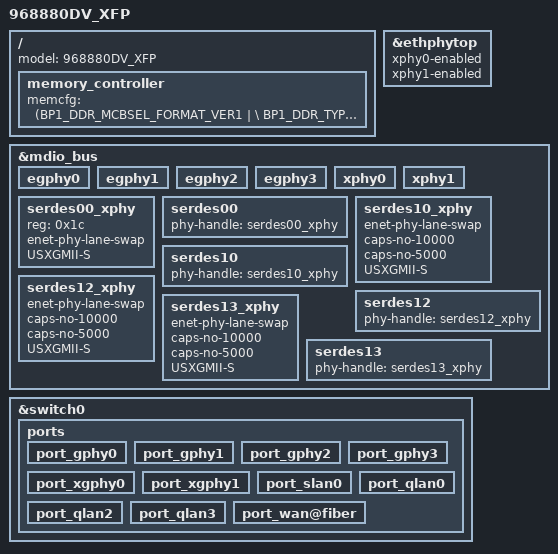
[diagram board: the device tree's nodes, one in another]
#include "inc/968880DV.dtsi"
#include "inc/968880DV_SFP.dtsi"

/ {
        memory_controller {
                memcfg = <(BP1_DDR_MCBSEL_FORMAT_VER1   | \
                           BP1_DDR_TYPE_LPDDR4         | \
                           BP1_DDR_SPEED_2133_36_39_39 | \
                           BP1_DDR_WIDTH_32BIT         | \
                           BP1_DDR_TOTAL_SIZE_8Gb      | \
                           BP1_DDR_SSC_CONFIG_1        | \
                           BP1_DDR_CONFIG_DEBUG)>;
        };
};

/ {
    model = "968880DV_XFP";
};

&ethphytop {
    xphy0-enabled;
    xphy1-enabled;
};

&mdio_bus {
    egphy0 {
        status = "okay";
    };
    egphy1 {
        status = "okay";
    };
    egphy2 {
        status = "okay";
    };
    egphy3 {
        status = "okay";
    };
    xphy0 {
        status = "okay";
    };
    xphy1 {
        status = "okay";
    };
    serdes00_xphy {
        reg = <0x1c>;
        enet-phy-lane-swap;
        USXGMII-S;
        status = "okay";
    };
    serdes00 {
        phy-handle = <&serdes00_xphy>;
        status = "okay";
    };
    serdes10_xphy {
        enet-phy-lane-swap;
        caps-no-10000;
        caps-no-5000;
        USXGMII-S;
        status = "okay";
    };
    serdes10 {
        phy-handle = <&serdes10_xphy>;
        status = "okay";
    };
    serdes12_xphy {
        enet-phy-lane-swap;
        caps-no-10000;
        caps-no-5000;
        USXGMII-S;
        status = "okay";
    };
    serdes12 {
        status = "okay";
        phy-handle = <&serdes12_xphy>;
    };
    serdes13_xphy {
        enet-phy-lane-swap;
        caps-no-10000;
        caps-no-5000;
        USXGMII-S;
        status = "okay";
    };
    serdes13 {
        status = "okay";
        phy-handle = <&serdes13_xphy>;
    };
};

&switch0 {
    ports {
        port_gphy0 {
            status = "okay";
        };
        port_gphy1 {
            status = "okay";
        };
        port_gphy2 {
            status = "okay";
        };
        port_gphy3 {
            status = "okay";
        };
        port_xgphy0 {
            status = "okay";
        };
        port_xgphy1 {
            status = "okay";
        };
        port_slan0 {
            status = "okay";
        };
        port_qlan0 {
            status = "okay";
        };
        port_qlan2 {
            status = "okay";
        };
        port_qlan3 {
            status = "okay";
        };
        port_wan@fiber {
            status = "okay";
        };
    };
};
